# CH32H417 register map
Vendor: WCH Ltd.; File version: 1.2
Registers are 32-bit, read-write, reset 0x0 unless marked. A register's access mark holds for its fields unless they carry their own. Offsets are from the block's base; [hi:lo] are bit positions; {n}, {i} and the like mark numbered series.

## PFIC — Programmable Fast Interrupt Controller
Base 0xE000E000
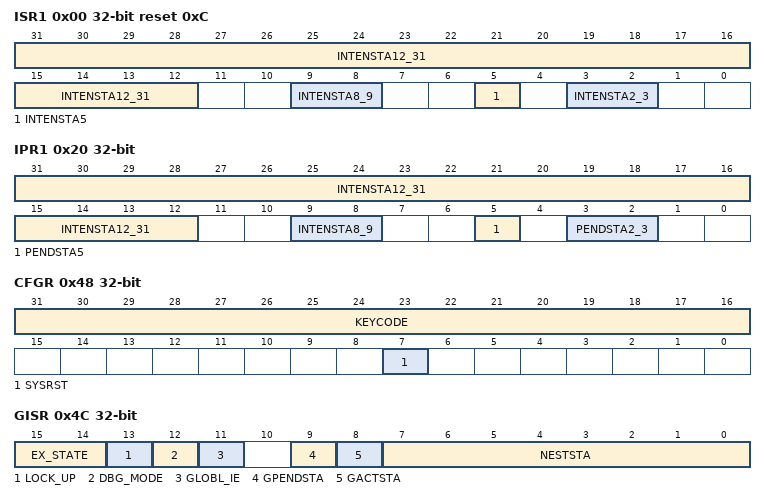
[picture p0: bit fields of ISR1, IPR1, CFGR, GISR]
0x00 ISR1 ro reset 0xC — Interrupt Status Register
  [31:12] INTENSTA12_31 — Interrupt ID Status
  [9:8] INTENSTA8_9 — Interrupt ID Status
  [5] INTENSTA5 — Interrupt ID Status
  [3:2] INTENSTA2_3 — Interrupt ID Status
0x04 ISR2 ro — Interrupt Status Register
  [31:0] INTENSTA — Interrupt ID Status
0x08 ISR3 ro — Interrupt Status Register
  [31:0] INTENSTA — Interrupt ID Status
0x0C ISR4 ro — Interrupt Status Register
  [31:0] INTENSTA — Interrupt ID Status
0x10 ISR5 ro — Interrupt Status Register
  [19:0] INTENSTA — Interrupt ID Status
0x20 IPR1 ro — Interrupt Pending Register
  [31:12] INTENSTA12_31 — PENDSTA
  [9:8] INTENSTA8_9 — PENDSTA
  [5] PENDSTA5 — PENDSTA
  [3:2] PENDSTA2_3 — PENDSTA
{0x1C+4i} IPR{i} ro (i=2..4) — Interrupt Pending Register
  [31:0] PENDSTA
0x30 IPR5 ro — Interrupt Pending Register
  [19:0] PENDSTA
0x40 ITHRESDR — Interrupt Priority Register
  [7:0] THRESHOLD
0x48 CFGR wo — Interrupt configuration register
  [31:16] KEYCODE
  [7] SYSRST — System reset register
0x4C GISR ro — Interrupt Global Register
  [15:14] EX_STATE — The kernel status register, which is used to obtain the running state of the kernel
  [13] LOCK_UP — lock-out state
  [12] DBG_MODE — debug mode
  [11] GLOBL_IE — global interrupt enable
  [9] GPENDSTA — interrupt pending
  [8] GACTSTA — interrupt execution
  [7:0] NESTSTA — interrupt nesting
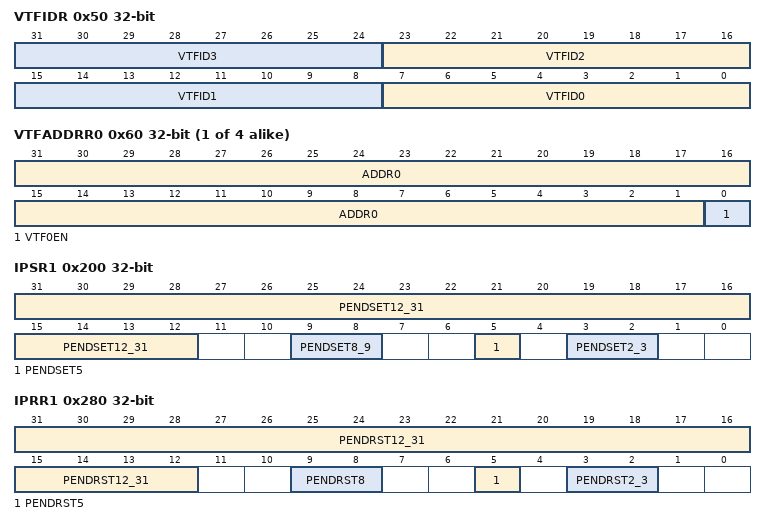
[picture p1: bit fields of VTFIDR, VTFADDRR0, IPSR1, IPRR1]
0x50 VTFIDR — ID Config Register
  [8n+7:8n] VTFID{n} (n=0..3)
{0x60+4i} VTFADDRR{i} (i=0..3) — Interrupt {i} address Register
  [31:1] ADDR{i}, [0] VTF{i}EN
0x100 IENR1 wo — Interrupt Setting Register
  [31:12] INTEN12_31
{0xFC+4i} IENR{i} wo (i=2..4) — Interrupt Setting Register
  [31:0] INTEN
0x110 IENR5 wo — Interrupt Setting Register
  [19:0] INTEN
0x180 IRER1 wo — Interrupt Clear Register
  [31:12] INTRSET12_31
{0x17C+4i} IRER{i} wo (i=2..4) — Interrupt Clear Register
  [31:0] INTRSET
0x190 IRER5 wo — Interrupt Clear Register
  [19:0] INTRSET
0x200 IPSR1 wo — Interrupt Pending Register
  [31:12] PENDSET12_31 — PENDSET
  [9:8] PENDSET8_9 — PENDSET
  [5] PENDSET5 — PENDSET
  [3:2] PENDSET2_3 — PENDSET
{0x1FC+4i} IPSR{i} wo (i=2..4) — Interrupt Pending Register
  [31:0] PENDSET
0x210 IPSR5 wo — Interrupt Pending Register
  [19:0] PENDSET
0x280 IPRR1 wo — Interrupt Pending Clear Register
  [31:12] PENDRST12_31 — PENDRESET
  [9:8] PENDRST8 — PENDRESET
  [5] PENDRST5 — PENDRESET
  [3:2] PENDRST2_3 — PENDRESET
{0x27C+4i} IPRR{i} wo (i=2..4) — Interrupt Pending Clear Register
  [31:0] PENDRST — PENDRESET
0x290 IPRR5 wo — Interrupt Pending Clear Register
  [19:0] PENDRST — PENDRESET
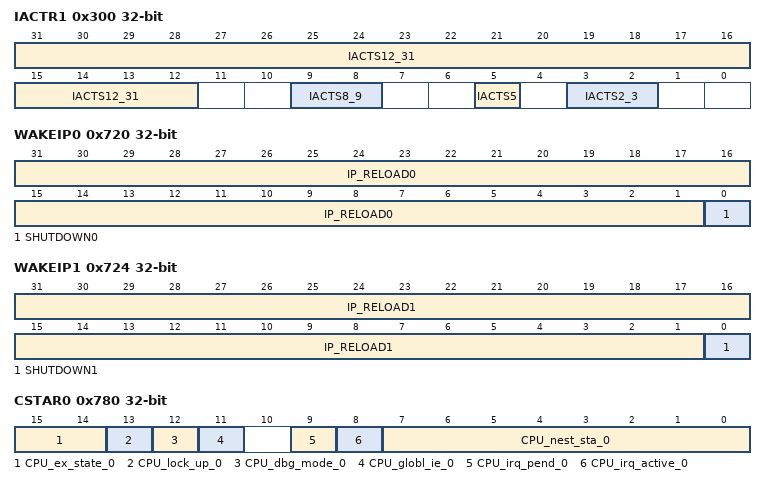
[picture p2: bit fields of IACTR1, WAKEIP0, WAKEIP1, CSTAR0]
0x300 IACTR1 wo — Interrupt ACTIVE Register
  [31:12] IACTS12_31 — IACTS
  [9:8] IACTS8_9 — IACTS
  [5] IACTS5 — IACTS
  [3:2] IACTS2_3 — IACTS
{0x2FC+4i} IACTR{i} wo (i=2..4) — Interrupt ACTIVE Register
  [31:0] IACTS
0x310 IACTR5 wo — Interrupt ACTIVE Register
  [19:0] IACTS
{0x400+4i} IPRIOR{i} (i=0..63) — Interrupt Priority Register
{0x600+4i} IALLOCR{i} ro (i=0..31) — Interrupt Allocation Register
{0x600+4i} IALLOCR{i} (i=32..63) — Interrupt Allocation Register
{0x6FC+4i} IAUTR{i} ro (i=1..5) — interrupts authority register {i}
  [31:0] IAUT — interrupt allocates all registers and is used to query whether the interrupt responds to each kernel allocation
0x720 WAKEIP0 — PFIC wake-up instruction pointer register 0
  [31:1] IP_RELOAD0 — The PC address register on kernel C0 wake-up, which is used to reload the PC value after power-on wake-up and reset wake-up
  [0] SHUTDOWN0 — Kernel C0 Deep Sleep (Locked) Cancellation Register
0x724 WAKEIP1 — PFIC wake-up instruction pointer register 1
  [31:1] IP_RELOAD1 — The PC address register on kernel C1 wake-up, which is used to reload the PC value after power-on wake-up and reset wake-up
  [0] SHUTDOWN1 — Kernel C1 Deep Sleep (Locked) Cancellation Register
0x780 CSTAR0 ro — PFIC kernel status register 0
  [15:14] CPU_ex_state_0 — The kernel C0 status register is used to obtain the running state of kernel C0
  [13] CPU_lock_up_0 — The kernel C0 lock status register is used to query whether kernel C0 is in the locked state
  [12] CPU_dbg_mode_0 — Kernel C0 debug mode register, which is used to query whether kernel C0 is in debug mode
  [11] CPU_globl_ie_0 — The kernel C0 global interrupt enable register is used to query whether the kernel C0 global interrupt is enabled
  [9] CPU_irq_pend_0 — Kernel C0 interrupt pending flag register, which is used to query kernel C1 for unhandled interrupts
  [8] CPU_irq_active_0 — Kernel C0 interrupt active flag register, which is used to query whether kernel C0 is processing interrupts
  [7:0] CPU_nest_sta_0 — The nested status register of kernel C0 interrupts is used to query the nested state of kernel C0 interrupts. nest_sta bits from the INEST_CTLR register of the CSR register
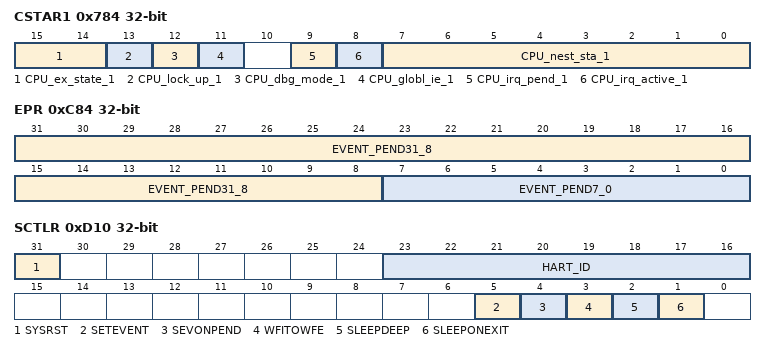
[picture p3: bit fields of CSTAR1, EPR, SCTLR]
0x784 CSTAR1 ro — PFIC kernel status register 1
  [15:14] CPU_ex_state_1 — The kernel C1 status register is used to obtain the running state of kernel C1
  [13] CPU_lock_up_1 — The kernel C1 lock status register is used to query whether kernel C1 is in the locked state
  [12] CPU_dbg_mode_1 — Kernel C1 debug mode register, which is used to query whether kernel C1 is in debug mode
  [11] CPU_globl_ie_1 — The kernel C1 global interrupt enable register is used to query whether the kernel C1 global interrupt is enabled
  [9] CPU_irq_pend_1 — Kernel C1 interrupt pending flag register, which is used to query kernel C1 for unhandled interrupts
  [8] CPU_irq_active_1 — Kernel C1 interrupt active flag register, which is used to query whether kernel C1 is processing interrupts
  [7:0] CPU_nest_sta_1 — The nested status register of kernel C1 interrupts is used to query the nested state of kernel C1 interrupts. nest_sta bits from the INEST_CTLR register of the CSR register
0xC80 EENR reset 0xFFFFFFFF — PFIC Event Enable Register
  [30:0] EVENTEN — 31-0 Event wake-up enabled
0xC84 EPR access per field — PFIC Event Suspend Register
  [31:8] EVENT_PEND31_8 rw — 31-8 event is suspended, write 1 to clear zero
  [7:0] EVENT_PEND7_0 ro — 7-0 Event Pending Status, Not Clearable
0xC88 EWUPR ro — PFIC Event Wake Register
  [31:0] EVENT_WUP — 31-0 Event Wake Register
0xD10 SCTLR — System Control Register
  [31] SYSRST — System reset
  [23:16] HART_ID — Kernel ID register, which is used to obtain the kernel ID of the reader register
  [5] SETEVENT
  [4] SEVONPEND
  [3] WFITOWFE — ues WFI as WFE
  [2] SLEEPDEEP — low power mode selection
  [1] SLEEPONEXIT — system leaves the state after an interruption
